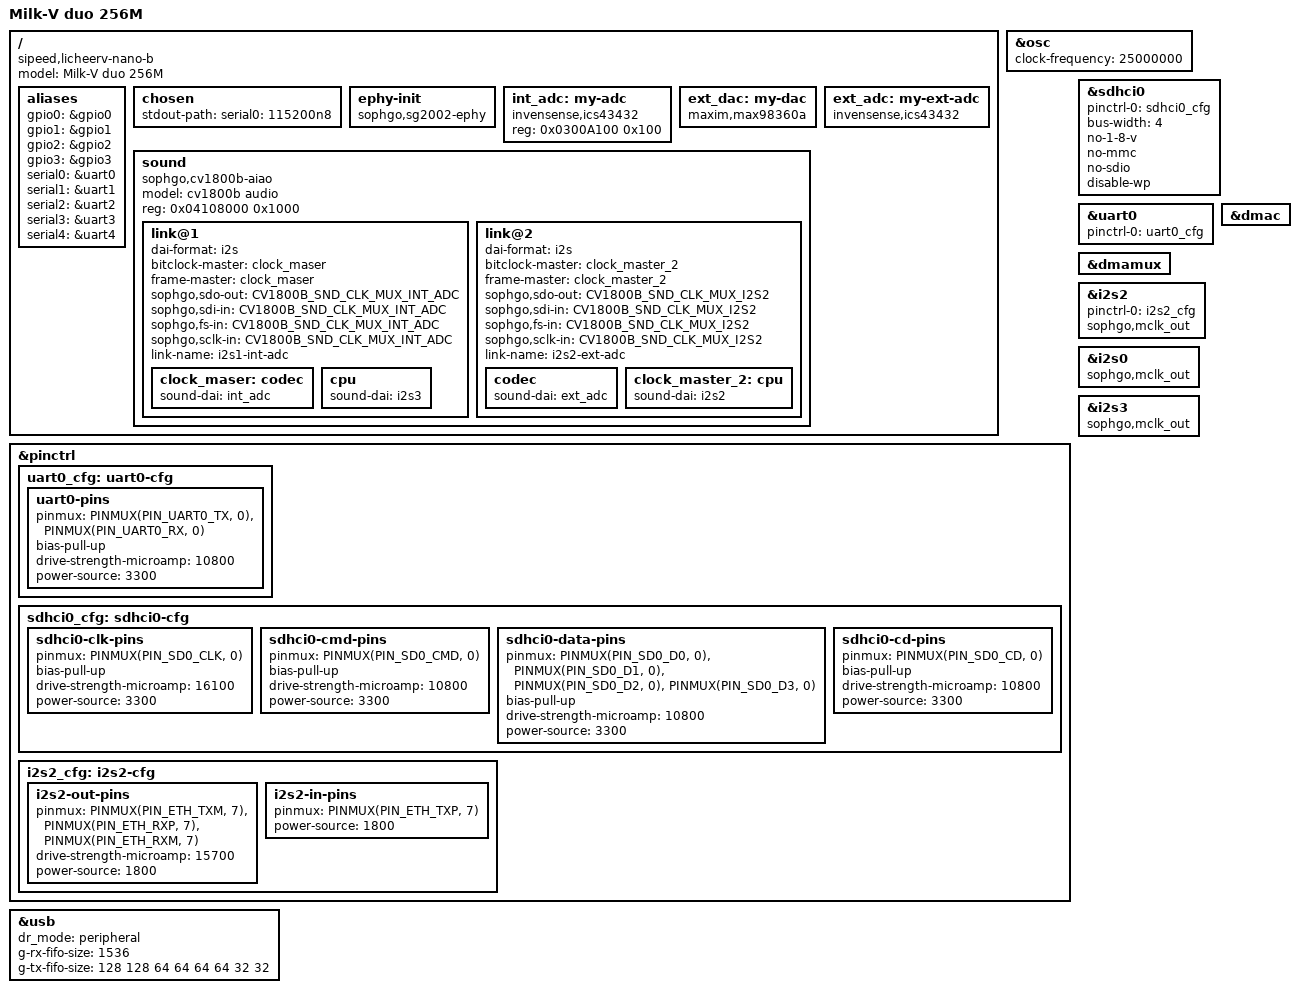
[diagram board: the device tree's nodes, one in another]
// SPDX-License-Identifier: (GPL-2.0 OR MIT)
/*
* Copyright (C) 2024 Thomas Bonnefille <thomas.bonnefille@bootlin.com>
*/

/dts-v1/;

#include "sg2002.dtsi"

/ {
	model = "Milk-V duo 256M";
	compatible = "sipeed,licheerv-nano-b",
	"sipeed,licheerv-nano",
	"sophgo,sg2002";

	aliases {
		gpio0 = &gpio0;
		gpio1 = &gpio1;
		gpio2 = &gpio2;
		gpio3 = &gpio3;
		serial0 = &uart0;
		serial1 = &uart1;
		serial2 = &uart2;
		serial3 = &uart3;
		serial4 = &uart4;
	};

	chosen {
		stdout-path = "serial0: 115200n8";
	};
};

&osc {
	clock-frequency = <25000000>;
};

&pinctrl {
	uart0_cfg: uart0-cfg {
		uart0-pins {
			pinmux = <PINMUX(PIN_UART0_TX, 0)>,
			<PINMUX(PIN_UART0_RX, 0)>;
			bias-pull-up;
			drive-strength-microamp = <10800>;
			power-source = <3300>;
		};
	};

	sdhci0_cfg: sdhci0-cfg {
		sdhci0-clk-pins {
			pinmux = <PINMUX(PIN_SD0_CLK, 0)>;
			bias-pull-up;
			drive-strength-microamp = <16100>;
			power-source = <3300>;
		};

		sdhci0-cmd-pins {
			pinmux = <PINMUX(PIN_SD0_CMD, 0)>;
			bias-pull-up;
			drive-strength-microamp = <10800>;
			power-source = <3300>;
		};

		sdhci0-data-pins {
			pinmux = <PINMUX(PIN_SD0_D0, 0)>,
			<PINMUX(PIN_SD0_D1, 0)>,
			<PINMUX(PIN_SD0_D2, 0)>,
			<PINMUX(PIN_SD0_D3, 0)>;
			bias-pull-up;
			drive-strength-microamp = <10800>;
			power-source = <3300>;
		};

		sdhci0-cd-pins {
			pinmux = <PINMUX(PIN_SD0_CD, 0)>;
			bias-pull-up;
			drive-strength-microamp = <10800>;
			power-source = <3300>;
		};
	};
};

&sdhci0 {
	pinctrl-0 = <&sdhci0_cfg>;
	pinctrl-names = "default";
	status = "okay";
	bus-width = <4>;
	no-1-8-v;
	no-mmc;
	no-sdio;
	disable-wp;
};

&usb {
	dr_mode = "peripheral";
	status = "okay";
	g-rx-fifo-size = <1536>;
	g-tx-fifo-size = <128 128 64 64 64 64 32 32>;
};

&uart0 {
	pinctrl-0 = <&uart0_cfg>;
	pinctrl-names = "default";
	status = "okay";
};

&dmac {
	status = "okay";
};

&dmamux {
	status = "okay";
};

&pinctrl {
	i2s2_cfg: i2s2-cfg {
		i2s2-out-pins {
			pinmux = <PINMUX(PIN_ETH_TXM, 7)>,
			<PINMUX(PIN_ETH_RXP,  7)>,
			<PINMUX(PIN_ETH_RXM,  7)>;

			drive-strength-microamp = <15700>;
			power-source = <1800>;
		};
		i2s2-in-pins {
			pinmux = <PINMUX(PIN_ETH_TXP, 7)>;
			power-source = <1800>;
		};
	};
};

/ {
	ephy-init {/// delete me!!!!
		compatible = "sophgo,sg2002-ephy";
	};

};

&i2s2 {
	pinctrl-0 = <&i2s2_cfg>;
	pinctrl-names = "default";
	#sound-dai-cells = <0>;
	sophgo,mclk_out;
	status = "okay";
};

&i2s0 {
	status = "okay";
	sophgo,mclk_out;
	#sound-dai-cells = <0>;
};
&i2s3 {
	status = "okay";
	sophgo,mclk_out;
	#sound-dai-cells = <0>;
};

/ {
	int_adc: my-adc {
		// compatible = "sophgo,cv1800b-adc-codec";
		compatible = "invensense,ics43432";

		#sound-dai-cells = <0>;
		reg = <0x0300A100 0x100>;

	};

	ext_dac: my-dac {
		compatible = "maxim,max98360a";
		#sound-dai-cells = <0>;
	};
	ext_adc: my-ext-adc {
		compatible = "invensense,ics43432";
		#sound-dai-cells = <0>;
	};

	sound {
		compatible = "sophgo,cv1800b-aiao";
		model = "cv1800b audio";
		reg = <0x04108000 0x1000>;
		link@1 {
			dai-format = "i2s";
			bitclock-master = <&clock_maser>;
			frame-master = <&clock_maser>;
			sophgo,sdo-out = <CV1800B_SND_CLK_MUX_INT_ADC>;
			sophgo,sdi-in = <CV1800B_SND_CLK_MUX_INT_ADC>;
			sophgo,fs-in = <CV1800B_SND_CLK_MUX_INT_ADC>;
			sophgo,sclk-in = <CV1800B_SND_CLK_MUX_INT_ADC>;
			link-name = "i2s1-int-adc";

			clock_maser: codec {
				sound-dai = <&int_adc>;

			};

			cpu {
				sound-dai = <&i2s3>;
			};

		};

		link@2 {
			dai-format = "i2s";
			bitclock-master = <&clock_master_2>;
			frame-master = <&clock_master_2>;
			sophgo,sdo-out = <CV1800B_SND_CLK_MUX_I2S2>;
			sophgo,sdi-in = <CV1800B_SND_CLK_MUX_I2S2>;
			sophgo,fs-in = <CV1800B_SND_CLK_MUX_I2S2>;
			sophgo,sclk-in = <CV1800B_SND_CLK_MUX_I2S2>;
			link-name = "i2s2-ext-adc";

			codec {
				sound-dai = <&ext_adc>;

			};

			clock_master_2: cpu {
				sound-dai = <&i2s2>;

			};

		};
	};
};
